# S6E2CC register map
File version: 1.1
Registers are 32-bit, read-write, reset 0x0 unless marked. A register's access mark holds for its fields unless they carry their own. Offsets are from the block's base; [hi:lo] are bit positions; {n}, {i} and the like mark numbered series; 'fields as' and 'values as' point back to an identical list.

## USBETHERCLK — USB/Ethernet Clock
Base 0x40036000
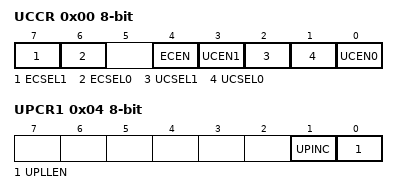
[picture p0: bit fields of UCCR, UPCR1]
0x00 UCCR 8-bit (reset mask 0x7F) — USB/Ethernet-PLL Clock Control Register
  [7] ECSEL1 — Ethernet clock selection bit 1
  [6] ECSEL0 — Ethernet clock selection bit 0
  [4] ECEN — Ethernet clock output enable bit
  [3] UCEN1 — USB1 clock output enable bit
  [2] UCSEL1 — USB1 clock selection bit
  [1] UCSEL0 — USB0 clock selection bit
  [0] UCEN0 — USB0 clock output enable bit
0x04 UPCR1 8-bit — USB/Ethernet-PLL Control Register 1
  [1] UPINC — USB/Ethernet-PLL input clock selection bit
  [0] UPLLEN — USB/Ethernet-PLL oscillation enable bit
0x08 UPCR2 8-bit — USB/Ethernet-PLL Control Register 2
  [2:0] UPOWT — USB/Ethernet-PLL oscillation stabilization wait time setting bit
0x0C UPCR3 8-bit — USB/Ethernet-PLL Control Register 3
  [4:0] UPLLK — Frequency division ratio (K) setting bit of the USB/Ethernet-PLL clock
0x10 UPCR4 8-bit reset 0x3B — USB/Ethernet-PLL Control Register 4
  [6:0] UPLLN — Frequency division ratio (N) setting bit of the USB/Ethernet-PLL clock
0x14 UP_STR 8-bit ro — USB/Ethernet-PLL Status Register
  [0] UPRDY — USB/Ethernet-PLL oscillation stabilization bit
0x18 UPINT_ENR 8-bit — USB/Ethernet-PLL Interrupt Source Enable Register
  [0] UPCSE — USB/Ethernet-PLL oscillation stabilization wait complete interrupt enable bit
0x1C UPINT_CLR 8-bit wo — USB/Ethernet-PLL Interrupt Source Clear Register
  [0] UPCSC — USB/Ethernet-PLL oscillation stabilization interrupt source clear bit
0x20 UPINT_STR 8-bit ro — ERROR!!!!!!!!!!!!!!!!!!!!
  [0] UPCSI
0x24 UPCR5 8-bit reset 0x4 — ERROR!!!!!!!!!!!!!!!!!!!!
  [3:0] UPLLM
0x28 UPCR6 8-bit reset 0x2 — ERROR!!!!!!!!!!!!!!!!!!!!
  [3:0] UBSR
0x2C UPCR7 8-bit — ERROR!!!!!!!!!!!!!!!!!!!!
  [0] EPLLEN
0x30 USBEN0 8-bit — ERROR!!!!!!!!!!!!!!!!!!!!
  [0] USBEN0
0x34 USBEN1 8-bit — ERROR!!!!!!!!!!!!!!!!!!!!
  [0] USBEN1

## DMAC — DMAC Registers
Base 0x40060000
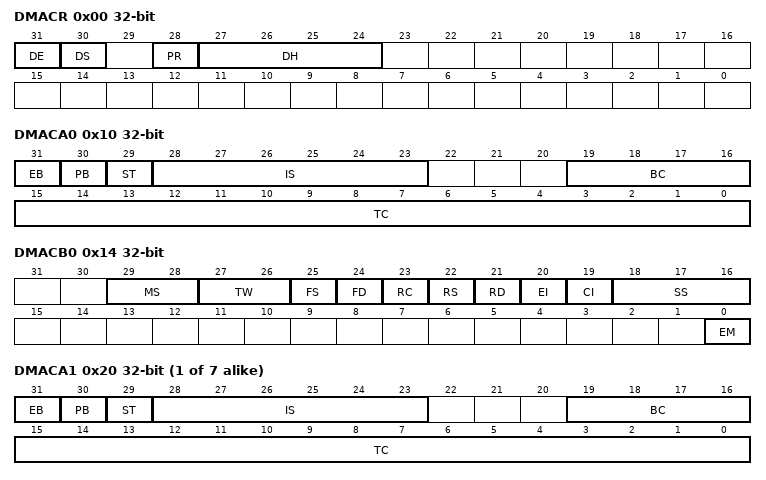
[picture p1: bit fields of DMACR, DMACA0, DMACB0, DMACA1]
0x00 DMACR — Entire DMAC Configuration Register
  [31] DE — DMA Enable (all-channel operation enable bit)
  [30] DS — DMA Stop
  [28] PR — Priority Rotation
  [27:24] DH — DMA Halt (All-channel pause bit)
0x10 DMACA0 — Configuration A Register
  [31] EB — Enable bit (individual-channel operation enable bit)
  [30] PB — Pause bit (individual-channel pause bit)
  [29] ST — Software Trigger
  [28:23] IS — Input Select
  [19:16] BC — Block Count
  [15:0] TC — Transfer Count
0x14 DMACB0 — Configuration B Register
  [29:28] MS — Mode Select
  [27:26] TW — Transfer Width
  [25] FS — Fixed Source
  [24] FD — Fixed Destination
  [23] RC — Reload Count (BC/TC reload)
  [22] RS — Reload Source
  [21] RD — Reload Destination
  [20] EI — Error Interrupt (unsuccessful transfer completion interrupt enable)
  [19] CI — Completion Interrupt (successful transfer completion interrupt enable)
  [18:16] SS — Stop Status (stop status notification)
  [0] EM — Enable bit Mask (EB bit clear mask)
0x18 DMACSA0 — Transfer Source Address Register
0x1C DMACDA0 — Transfer Destination Address Register
{0x10+0x10*i} DMACA{i} (i=1..7) — Configuration A Register {i}
  fields as DMACA0
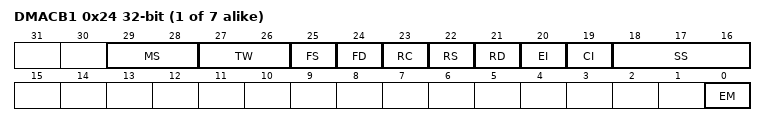
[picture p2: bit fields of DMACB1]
{0x14+0x10*i} DMACB{i} (i=1..7) — Configuration B Register {i}
  fields as DMACB0
{0x18+0x10*i} DMACSA{i} (i=1..7) — Transfer Source Address Register {i}
{0x1C+0x10*i} DMACDA{i} (i=1..7) — Transfer Destination Address Register {i}

## DSTC — DSTC registers
Base 0x40061000
0x00 DESTP — Descriptor top address Register
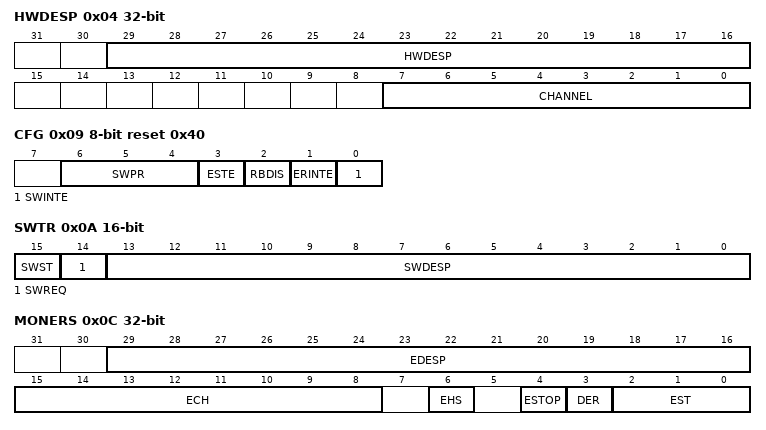
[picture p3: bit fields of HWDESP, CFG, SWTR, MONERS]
0x04 HWDESP — Hardware DES pointer Register
  [29:16] HWDESP, [7:0] CHANNEL
0x08 CMD 8-bit reset 0x1 — Command Register
0x09 CFG 8-bit reset 0x40 — Configuration Register
  [6:4] SWPR — Software transfer priority
  [3] ESTE — Error stop enable
  [2] RBDIS — Read skip buffer disable
  [1] ERINTE — Error interrupt enable
  [0] SWINTE — Software interrupt enable
0x0A SWTR 16-bit — Software trigger Register
  [15] SWST ro — Software status
  [14] SWREQ ro — Software request
  [13:0] SWDESP — Software DES pointer
0x0C MONERS
  [29:16] EDESP ro — Error DES pointer
  [15:8] ECH ro — Error hardware channel
  [6] EHS ro — Error hardware software
  [4] ESTOP ro — Error stop
  [3] DER ro — Double error
  [2:0] EST ro — Error status
{0x10+4i} DREQENB{i} (i=0..7) — DMA request enable Register {i}
{0x30+4i} HWINT{i} (i=0..7) — Hardware transfer interrupt Register {i}
{0x50+4i} HWINTCLR{i} (i=0..7) — Hardware transfer interrupt clear Register {i}
{0x70+4i} DQMSK{i} (i=0..7) — DMA request mask Register {i}
{0x90+4i} DQMSKCLR{i} (i=0..7) — DMA request mask clear Register {i}

## CANPRES — CAN Prescaler Register
Base 0x40037000
0x00 CANPRE 8-bit reset 0xB — CAN Prescaler Register
  [3:0] CANPRE — CAN prescaler setting bits

## ETHERNET_CONTROL — Ethernet system control
Base 0x40066000
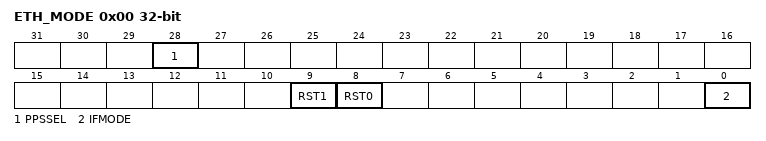
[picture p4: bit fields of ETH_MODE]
0x00 ETH_MODE — Mode Select Register
  [28] PPSSEL — Select either of the system time counter pulse outputs of the Ethernet-MAC PTP function to output to E_PPS0_PPS1 pin
  [9] RST1 — reset signal against Ethernet-MAC (ch.1)
  [8] RST0 — reset signal against Ethernet-MAC (ch.0)
  [0] IFMODE — Mode selector
0x08 ETH_CLKG — Clock Gating Register
  [1:0] MACEN — Select the system clock supply to Ethernet-MAC

## I2SPRE — I2S Clock Generation
Base 0x4003D000
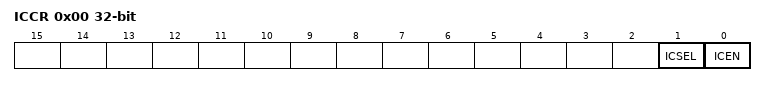
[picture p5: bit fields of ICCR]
0x00 ICCR — I2S Clock Control Register
  [1] ICSEL — I2S clock selection bit
  [0] ICEN — I2S clock output enable bit
0x04 IPCR1 — I2S-PLL Control Register 1
  [0] IPLLEN — I2S-PLL oscillation enable bit
0x08 IPCR2 — I2S-PLL Control Register 2
  [2:0] IPOWT — I2S-PLL oscillation stabilization wait time setting bits
0x0C IPCR3 reset 0x1 — I2S-PLL Control Register 3
  [4:0] IPLLK — Frequency division ratio (K) setting bits of the I2S-PLL clock
0x10 IPCR4 reset 0x1F — I2S-PLL Control Register 4
  [6:0] IPLLN — Frequency division ratio (N) setting bits of the I2S-PLL clock
0x14 IP_STR — I2S-PLL Status Register
  [0] IPRDY ro — I2S-PLL oscillation stabilization bit
0x18 IPINT_ENR — I2S-PLL Interrupt Factor Enable Register
  [0] IPCSE — I2S-PLL oscillation stabilization wait complete interrupt enable bit
0x1C IPINT_CLR — I2S-PLL Interrupt Factor Status Register
  [0] IPCSC wo — I2S-PLL interrupt factor status bit
0x20 IPINT_STR — I2S-PLL Interrupt Factor Clear Register
  [0] IPCSI ro — I2S-PLL oscillation stabilization interrupt factor clear bit
0x24 IPCR5 reset 0x18 — I2S-PLL Control Register 5
  [6:0] IPLLM — Frequency division ratio (M) setting bits of the I2S-PLL clock

## SDIF — SD Card Interface
Base 0x4006E000
0x00 DUMMY reset not defined

## PCRC — 0
Base 0x40080000
0x00 PRGCRC_POLY reset 0x4C11DB7 — CRC Computing Generator Polynomial Register
0x04 PRGCRC_SEED reset 0xFFFFFFFF — CRC Computing Initial Value Register
0x08 PRGCRC_FXOR reset 0xFFFFFFFF — CRC Computing Resault XOR Value Register
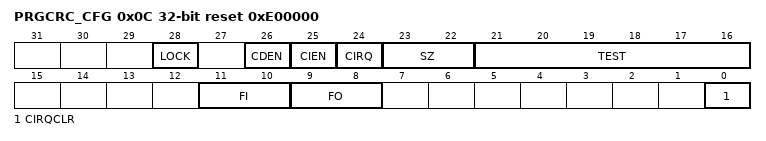
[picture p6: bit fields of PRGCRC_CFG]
0x0C PRGCRC_CFG reset 0xE00000 — CRC Computing Configuration Register
  [28] LOCK ro
  [26] CDEN — DMA request enable
  [25] CIEN — Interrupt request enable
  [24] CIRQ ro — Interrupt request
  [23:22] SZ — Input data size
  [21:16] TEST
  [11:10] FI — Input data format
  [9:8] FO — output data format
  [0] CIRQCLR wo — Interrupt request clear
0x10 PRGCRC_WR — CRC Computing Input Data Register
0x14 PRGCRC_RD — CRC Computing Output Data Register

## Notices in the file
Copyright (C) 2014 Spansion LLC. All Rights Reserved.
This software is owned and published by:
Spansion LLC, 915 DeGuigne Dr. Sunnyvale, CA  94088-3453 ("Spansion").
BY DOWNLOADING, INSTALLING OR USING THIS SOFTWARE, YOU AGREE TO BE BOUND
BY ALL THE TERMS AND CONDITIONS OF THIS AGREEMENT.
This software contains source code for use with Spansion
components. This software is licensed by Spansion to be adapted only
for use in systems utilizing Spansion components. Spansion shall not be
responsible for misuse or illegal use of this software for devices not
supported herein.  Spansion is providing this software "AS IS" and will
not be responsible for issues arising from incorrect user implementation
of the software.
SPANSION MAKES NO WARRANTY, EXPRESS OR IMPLIED, ARISING BY LAW OR OTHERWISE,
REGARDING THE SOFTWARE (INCLUDING ANY ACOOMPANYING WRITTEN MATERIALS),
ITS PERFORMANCE OR SUITABILITY FOR YOUR INTENDED USE, INCLUDING,
WITHOUT LIMITATION, THE IMPLIED WARRANTY OF MERCHANTABILITY, THE IMPLIED
WARRANTY OF FITNESS FOR A PARTICULAR PURPOSE OR USE, AND THE IMPLIED
WARRANTY OF NONINFRINGEMENT.
SPANSION SHALL HAVE NO LIABILITY (WHETHER IN CONTRACT, WARRANTY, TORT,
NEGLIGENCE OR OTHERWISE) FOR ANY DAMAGES WHATSOEVER (INCLUDING, WITHOUT
LIMITATION, DAMAGES FOR LOSS OF BUSINESS PROFITS, BUSINESS INTERRUPTION,
LOSS OF BUSINESS INFORMATION, OR OTHER PECUNIARY LOSS) ARISING FROM USE OR
INABILITY TO USE THE SOFTWARE, INCLUDING, WITHOUT LIMITATION, ANY DIRECT,
INDIRECT, INCIDENTAL, SPECIAL OR CONSEQUENTIAL DAMAGES OR LOSS OF DATA,
SAVINGS OR PROFITS,
EVEN IF SPANSION HAS BEEN ADVISED OF THE POSSIBILITY OF SUCH DAMAGES.
YOU ASSUME ALL RESPONSIBILITIES FOR SELECTION OF THE SOFTWARE TO ACHIEVE YOUR
INTENDED RESULTS, AND FOR THE INSTALLATION OF, USE OF, AND RESULTS OBTAINED
FROM, THE SOFTWARE.
This software may be replicated in part or whole for the licensed use,
with the restriction that this Disclaimer and Copyright notice must be
included with each copy of this software, whether used in part or whole,
at all times.
